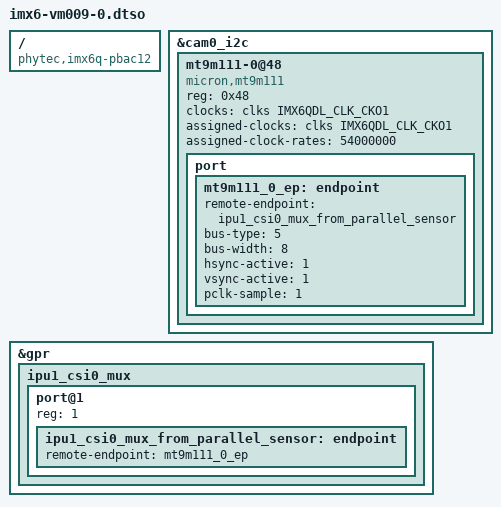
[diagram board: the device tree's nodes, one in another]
// SPDX-License-Identifier: (GPL-2.0+ OR MIT)
/*
 * Copyright (C) 2021 PHYTEC Messtechnik GmbH
 * Author: Stefan Riedmueller <s.riedmueller@phytec.de>
 */

/dts-v1/;
/plugin/;

#include <dt-bindings/clock/imx6qdl-clock.h>

/ {
	compatible = "phytec,imx6q-pbac12", "phytec,imx6dl-pbac12",
		     "phytec,imx6q-pbac06", "phytec,imx6dl-pbac06",
		     "phytec,imx6q-pbab01", "phytec,imx6dl-pbab01";
};

&cam0_i2c {
	#address-cells = <1>;
	#size-cells = <0>;

	mt9m111-0@48 {
		compatible = "micron,mt9m111";
		reg = <0x48>;

		clocks = <&clks IMX6QDL_CLK_CKO1>;
		clock-names = "mclk";

		assigned-clocks = <&clks IMX6QDL_CLK_CKO1>;
		assigned-clock-rates = <54000000>;

		port {
			mt9m111_0_ep: endpoint {
				remote-endpoint = <&ipu1_csi0_mux_from_parallel_sensor>;
				bus-type = <5>; /* Parallel */
				bus-width = <8>;
				hsync-active = <1>;
				vsync-active = <1>;
				pclk-sample = <1>;
			};
		};
	};
};

&gpr {
	ipu1_csi0_mux {
		#address-cells = <1>;
		#size-cells = <0>;

		port@1 {
			reg = <1>;
			ipu1_csi0_mux_from_parallel_sensor: endpoint {
				remote-endpoint = <&mt9m111_0_ep>;
			};
		};
	};
};
